VERSION ""

NS_ :

BS_:

BU_: Device Host

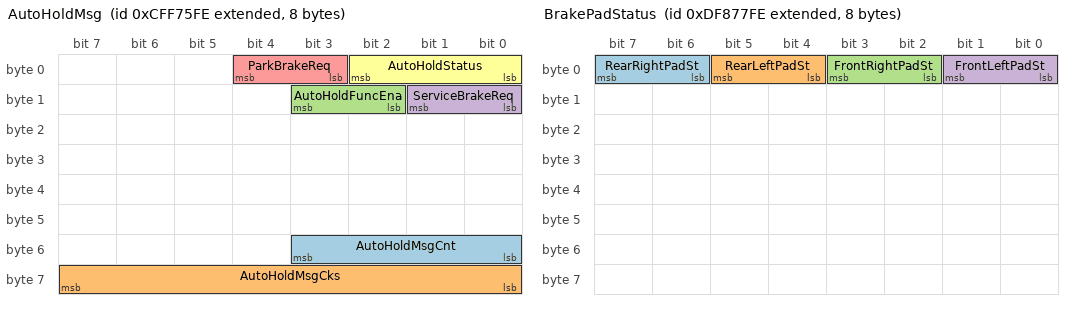
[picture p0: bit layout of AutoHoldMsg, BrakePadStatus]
BO_ 2365552126 AutoHoldMsg: 8 Vector__XXX
 SG_ AutoHoldMsgCnt : 48|4@1+ (1,0) [0|15] "" Vector__XXX
 SG_ AutoHoldMsgCks : 56|8@1+ (1,0) [0|255] "" Vector__XXX
 SG_ AutoHoldFuncEna : 10|2@1+ (1,0) [0|3] "" Vector__XXX
 SG_ ServiceBrakeReq : 8|2@1+ (1,0) [0|3] "" Vector__XXX
 SG_ ParkBrakeReq : 3|2@1+ (1,0) [0|3] "" Vector__XXX
 SG_ AutoHoldStatus : 0|3@1+ (1,0) [0|4] "" Vector__XXX

BO_ 2381870590 ParkBrakeMsg: 8 Vector__XXX
 SG_ ParkBrakeState : 0|2@1+ (1,0) [0|3] "" Vector__XXX

BO_ 2381870846 ServiceBrakeMsg: 8 Vector__XXX
 SG_ BrakePedalState : 2|2@1+ (1,0) [0|3] "" Vector__XXX
 SG_ ServiceBrakeState : 0|2@1+ (1,0) [0|3] "" Vector__XXX

BO_ 2381871102 BrakePadStatus: 8 Vector__XXX
 SG_ RearRightPadSt : 6|2@1+ (1,0) [0|3] "" Vector__XXX
 SG_ RearLeftPadSt : 4|2@1+ (1,0) [0|3] "" Vector__XXX
 SG_ FrontRightPadSt : 2|2@1+ (1,0) [0|3] "" Vector__XXX
 SG_ FrontLeftPadSt : 0|2@1+ (1,0) [0|3] "" Vector__XXX

CM_ "Arrival Bus Drivetrain System Database";
CM_ BO_ 2365552126 "E2E protection: Autosar 1A
DATAID: 0xF75";
CM_ SG_ 2365552126 AutoHoldMsgCnt "E2E Counter";
CM_ SG_ 2365552126 AutoHoldMsgCks "E2E CRC";
BA_DEF_  "BusType" STRING ;
BA_DEF_  "DBName" STRING ;
BA_DEF_  "DatabaseVersion" STRING ;
BA_DEF_ BO_  "GenMsgCycleTime" INT 0 3600000;
BA_DEF_ BO_  "Producer" STRING ;
BA_DEF_ BO_  "GenMsgILSupport" ENUM  "No","Yes";
BA_DEF_ BO_  "GenMsgRequestable" INT 0 1;
BA_DEF_ BO_  "GenMsgSendType" ENUM  "cyclic","NotUsed","NotUsed","NotUsed","NotUsed","NotUsed","NotUsed","IfActive","noMsgSendType";
BA_DEF_ SG_  "GenSigEVName" STRING ;
BA_DEF_ SG_  "GenSigILSupport" ENUM  "No","Yes";
BA_DEF_ SG_  "GenSigSendType" ENUM  "Cyclic","OnWrite","OnWriteWithRepetition","OnChange","OnChangeWithRepetition","IfActive","IfActiveWithRepetition","NoSigSendType";
BA_DEF_ SG_  "GenSigStartValue" INT 0 2147483647;
BA_DEF_ BU_  "NmStationAddress" INT 0 255;
BA_DEF_  "ProtocolType" STRING ;
BA_DEF_  "SAE_J1939_21_SpecVersion" STRING ;
BA_DEF_  "SAE_J1939_71_SpecVersion" STRING ;
BA_DEF_  "SAE_J1939_73_SpecVersion" STRING ;
BA_DEF_  "SAE_J1939_75_SpecVersion" STRING ;
BA_DEF_  "SAE_J1939_81_SpecVersion" STRING ;
BA_DEF_  "SAE_J1939_DA_SpecVersion" STRING ;
BA_DEF_ SG_  "SigType" ENUM  "Default","Range","RangeSigned","ASCII","Discrete","Control","ReferencePGN","DTC","StringDelimiter","StringLength","StringLengthControl","MessageCounter","MessageChecksum";
BA_DEF_ BO_  "VFrameFormat" ENUM  "StandardCAN","ExtendedCAN","reserved","J1939PG","reserved","reserved","reserved","reserved","reserved","reserved","reserved","reserved","reserved","reserved","StandardCAN_FD","ExtendedCAN_FD";
BA_DEF_DEF_  "BusType" "";
BA_DEF_DEF_ "Producer" "BRK" ;
BA_DEF_DEF_  "DBName" "";
BA_DEF_DEF_  "DatabaseVersion" "";
BA_DEF_DEF_  "GenMsgCycleTime" 0;
BA_DEF_DEF_  "GenMsgILSupport" "Yes";
BA_DEF_DEF_  "GenMsgRequestable" 1;
BA_DEF_DEF_  "GenMsgSendType" "noMsgSendType";
BA_DEF_DEF_  "GenSigEVName" "Env@Nodename_@Signame";
BA_DEF_DEF_  "GenSigILSupport" "Yes";
BA_DEF_DEF_  "GenSigSendType" "NoSigSendType";
BA_DEF_DEF_  "GenSigStartValue" 0;
BA_DEF_DEF_  "NmStationAddress" 254;
BA_DEF_DEF_  "ProtocolType" "";
BA_DEF_DEF_  "SAE_J1939_21_SpecVersion" "";
BA_DEF_DEF_  "SAE_J1939_71_SpecVersion" "";
BA_DEF_DEF_  "SAE_J1939_73_SpecVersion" "";
BA_DEF_DEF_  "SAE_J1939_75_SpecVersion" "";
BA_DEF_DEF_  "SAE_J1939_81_SpecVersion" "";
BA_DEF_DEF_  "SAE_J1939_DA_SpecVersion" "";
BA_DEF_DEF_  "SigType" "Default";
BA_DEF_DEF_  "VFrameFormat" "J1939PG";
BA_ "SAE_J1939_DA_SpecVersion" "2015-01";
BA_ "SAE_J1939_81_SpecVersion" "2012-05";
BA_ "SAE_J1939_75_SpecVersion" "2012-05";
BA_ "SAE_J1939_73_SpecVersion" "2012-10";
BA_ "SAE_J1939_71_SpecVersion" "2012-10";
BA_ "SAE_J1939_21_SpecVersion" "2006-10";
BA_ "ProtocolType" "J1939";
BA_ "DatabaseVersion" "1.0";
BA_ "BusType" "CAN";
BA_ "DBName" "DrivetrainSystem";
BA_ "GenMsgCycleTime" BO_ 2365552126 50;
BA_ "GenMsgSendType" BO_ 2365552126 0;
BA_ "GenMsgCycleTime" BO_ 2381870590 50;
BA_ "GenMsgSendType" BO_ 2381870590 0;
BA_ "GenMsgCycleTime" BO_ 2381870846 50;
BA_ "GenMsgSendType" BO_ 2381870846 0;
BA_ "GenMsgCycleTime" BO_ 2381871102 500;
BA_ "GenMsgSendType" BO_ 2381871102 0;
BA_ "SigType" SG_ 2365552126 AutoHoldMsgCnt 11;
BA_ "SigType" SG_ 2365552126 AutoHoldMsgCks 12;
VAL_ 2365552126 AutoHoldFuncEna 3 "NA" 2 "Reserved" 1 "Enabled" 0 "Disabled" ;
VAL_ 2365552126 ServiceBrakeReq 3 "Take_no_action" 2 "Reserved" 1 "On" 0 "Off" ;
VAL_ 2365552126 ParkBrakeReq 3 "Take_no_action" 2 "Reserved" 1 "On" 0 "Off" ;
VAL_ 2365552126 AutoHoldStatus 4 "NotAvailable" 3 "Fault" 2 "Active" 1 "Engaged" 0 "Disabled" ;
VAL_ 2381870590 ParkBrakeState 3 "Not_available" 2 "Error" 1 "On" 0 "Off" ;
VAL_ 2381870846 BrakePedalState 3 "Not_available" 2 "Error" 1 "On" 0 "Off" ;
VAL_ 2381870846 ServiceBrakeState 3 "Not_available" 2 "Error" 1 "On" 0 "Off" ;
VAL_ 2381871102 RearRightPadSt 3 "NA" 2 "Error" 1 "Warn" 0 "Ok" ;
VAL_ 2381871102 RearLeftPadSt 3 "NA" 2 "Error" 1 "Warn" 0 "Ok" ;
VAL_ 2381871102 FrontRightPadSt 3 "NA" 2 "Error" 1 "Warn" 0 "Ok" ;
VAL_ 2381871102 FrontLeftPadSt 3 "NA" 2 "Error" 1 "Warn" 0 "Ok" ;
